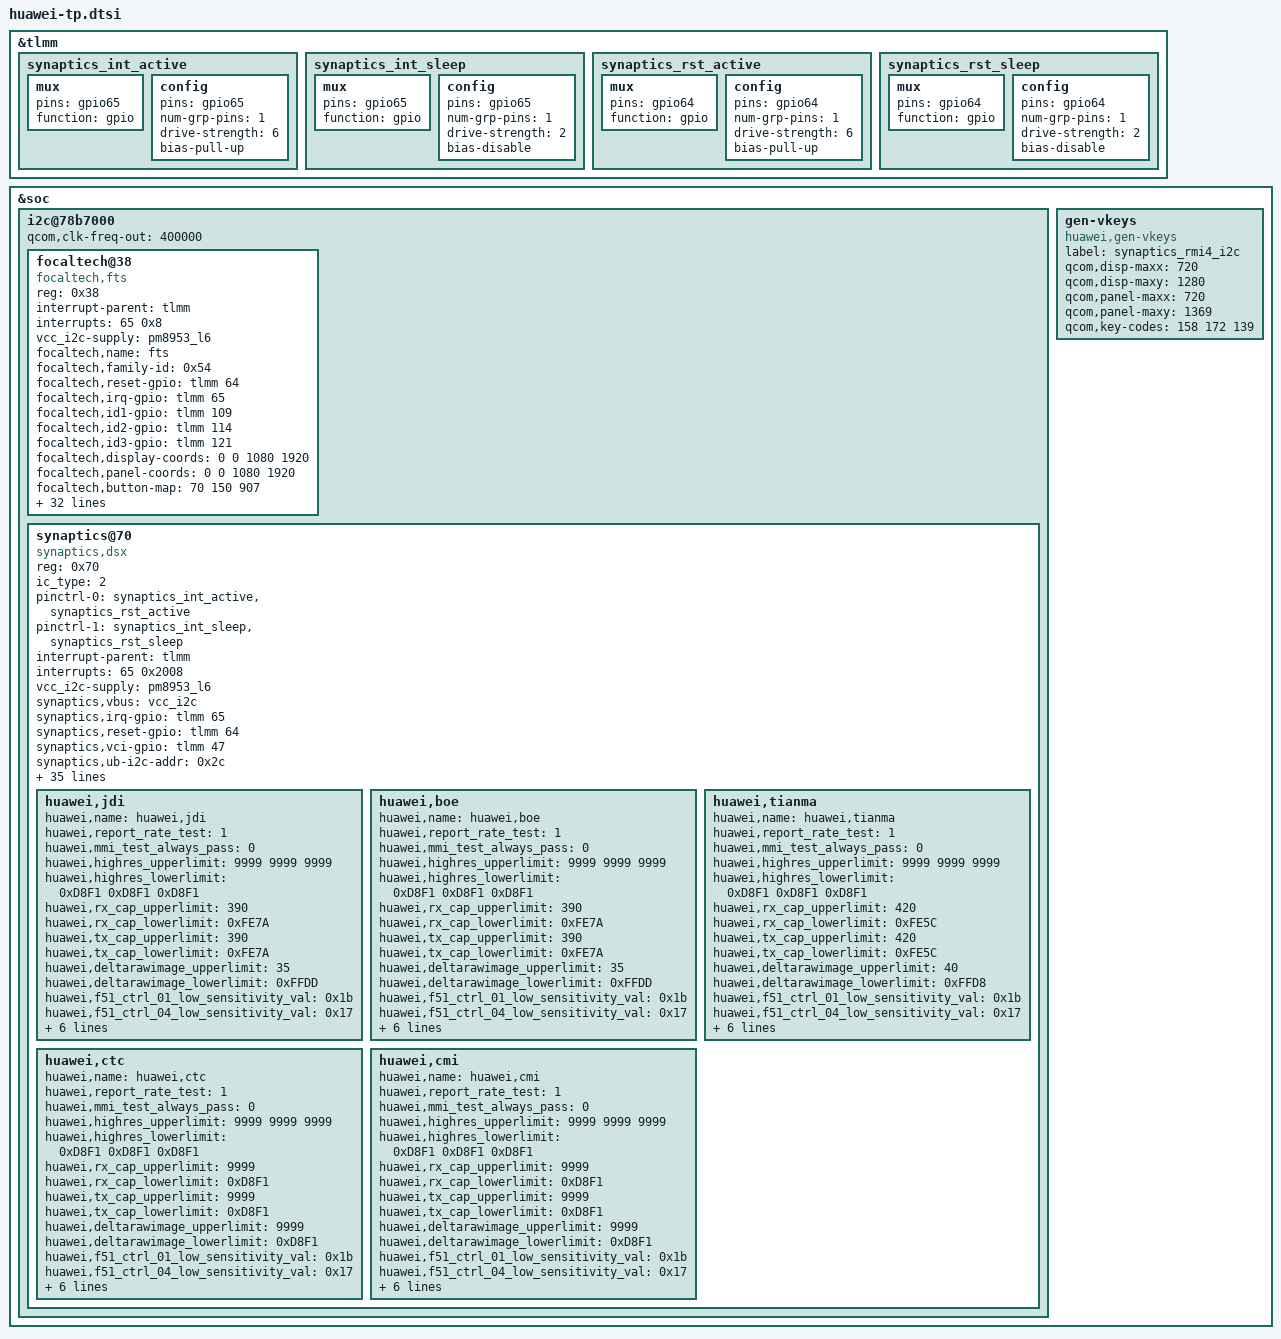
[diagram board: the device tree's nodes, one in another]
/* Modify JDI tp/lcd power on/off to reduce power consumption */
/* Modify JDI tp reset gpio pinctrl for power consumption */
/*Ath TP not working in glove mode*/
/* move l16 control to ATH device config file */
&tlmm {
	synaptics_int_active: synaptics_int_active{
			mux {
				pins = "gpio65";
				function =  "gpio";
			};
			config {
				pins = "gpio65";
				num-grp-pins = <1>;
				drive-strength = <6>;
				bias-pull-up;
		};
	};
	synaptics_int_sleep: synaptics_int_sleep {
			mux {
				pins = "gpio65";
				function =  "gpio";
			};
			config {
				pins = "gpio65";
				num-grp-pins = <1>;
				drive-strength = <2>;
				bias-disable;
		};
	};
	synaptics_rst_active: synaptics_rst_active {
			mux {
				pins = "gpio64";
				function =  "gpio";
			};
			config {
				pins = "gpio64";
				num-grp-pins = <1>;
				drive-strength = <6>;
				bias-pull-up;
			};
		};
	synaptics_rst_sleep: synaptics_rst_sleep {
			mux {
				pins = "gpio64";
				function =  "gpio";
			};
			config {
				pins = "gpio64";
				num-grp-pins = <1>;
				drive-strength = <2>;
				bias-disable;
		};
	};
};

&soc {
	i2c@78b7000 { /* BLSP1 QUP5 */
		status = "ok";
		#address-cells = <1>;
		#size-cells = <0>;
		qcom,clk-freq-out = <400000>;
		focaltech@38 {
			compatible = "focaltech,fts";
			reg = <0x38>;
			interrupt-parent = <&tlmm>;
			interrupts = <65 0x8>;
			vcc_i2c-supply = <&pm8953_l6>;
			focaltech,name = "fts";
			focaltech,family-id = <0x54>;
			focaltech,reset-gpio = <&tlmm 64 0x00>;
			focaltech,irq-gpio =<&tlmm 65 0x00>;
			focaltech,id1-gpio = <&tlmm 109 0x00>;
			focaltech,id2-gpio = <&tlmm 114 0x00>;
			focaltech,id3-gpio = <&tlmm 121 0x00>;
			focaltech,display-coords = <0 0 1080 1920>;
			focaltech,panel-coords = <0 0 1080 1920>;
			focaltech,button-map= <70 150 907>;
			focaltech,no-force-update;
			focaltech,i2c-pull-up;
			focaltech,group-id = <1>;
			focaltech,hard-reset-delay-ms = <20>;
			focaltech,soft-reset-delay-ms = <150>;
			focaltech,num-max-touches = <10>;
			focaltech,fw-name = "FT_Upgrade_App.i";
			focaltech,fw-delay-aa-ms = <50>;
			focaltech,fw-delay-55-ms = <30>;
			focaltech,fw-upgrade-id1 = <0x79>;
			focaltech,fw-upgrade-id2 = <0x03>;
			focaltech,fw-delay-readid-ms = <10>;
			focaltech,fw-delay-era-flsh-ms = <2000>;
			focaltech,channel_Xnum = <18>;
			focaltech,channel_Ynum = <30>;
			focaltech,cbunif_maxmin = <27>;
			focaltech,cbunif_chx_linearity = <70>;
			focaltech,cbunif_chy_linearity = <70>;
			focaltech,fullraw_upperlimit =
				<10000 10000 10000 10000 10000 10000 10000 10000 10000 10000 10000 10000 10000 10000 10000 10000 10000 10000 10000 10000 10000 10000 10000 10000 10000 10000 10000 10000 10000 10000
				10000 10000 10000 10000 10000 10000 10000 10000 10000 10000 10000 10000 10000 10000 10000 10000 10000 10000 10000 10000 10000 10000 10000 10000 10000 10000 10000 10000 10000 10000
				10000 10000 10000 10000 10000 10000 10000 10000 10000 10000 10000 10000 10000 10000 10000 10000 10000 10000 10000 10000 10000 10000 10000 10000 10000 10000 10000 10000 10000 10000
				10000 10000 10000 10000 10000 10000 10000 10000 10000 10000 10000 10000 10000 10000 10000 10000 10000 10000 10000 10000 10000 10000 10000 10000 10000 10000 10000 10000 10000 10000
				10000 10000 10000 10000 10000 10000 10000 10000 10000 10000 10000 10000 10000 10000 10000 10000 10000 10000 10000 10000 10000 10000 10000 10000 10000 10000 10000 10000 10000 10000
				10000 10000 10000 10000 10000 10000 10000 10000 10000 10000 10000 10000 10000 10000 10000 10000 10000 10000 10000 10000 10000 10000 10000 10000 10000 10000 10000 10000 10000 10000
				10000 10000 10000 10000 10000 10000 10000 10000 10000 10000 10000 10000 10000 10000 10000 10000 10000 10000 10000 10000 10000 10000 10000 10000 10000 10000 10000 10000 10000 10000
				10000 10000 10000 10000 10000 10000 10000 10000 10000 10000 10000 10000 10000 10000 10000 10000 10000 10000 10000 10000 10000 10000 10000 10000 10000 10000 10000 10000 10000 10000
				10000 10000 10000 10000 10000 10000 10000 10000 10000 10000 10000 10000 10000 10000 10000 10000 10000 10000 10000 10000 10000 10000 10000 10000 10000 10000 10000 10000 10000 10000
				10000 10000 10000 10000 10000 10000 10000 10000 10000 10000 10000 10000 10000 10000 10000 10000 10000 10000 10000 10000 10000 10000 10000 10000 10000 10000 10000 10000 10000 10000
				10000 10000 10000 10000 10000 10000 10000 10000 10000 10000 10000 10000 10000 10000 10000 10000 10000 10000 10000 10000 10000 10000 10000 10000 10000 10000 10000 10000 10000 10000
				10000 10000 10000 10000 10000 10000 10000 10000 10000 10000 10000 10000 10000 10000 10000 10000 10000 10000 10000 10000 10000 10000 10000 10000 10000 10000 10000 10000 10000 10000
				10000 10000 10000 10000 10000 10000 10000 10000 10000 10000 10000 10000 10000 10000 10000 10000 10000 10000 10000 10000 10000 10000 10000 10000 10000 10000 10000 10000 10000 10000
				10000 10000 10000 10000 10000 10000 10000 10000 10000 10000 10000 10000 10000 10000 10000 10000 10000 10000 10000 10000 10000 10000 10000 10000 10000 10000 10000 10000 10000 10000
				10000 10000 10000 10000 10000 10000 10000 10000 10000 10000 10000 10000 10000 10000 10000 10000 10000 10000 10000 10000 10000 10000 10000 10000 10000 10000 10000 10000 10000 10000
				10000 10000 10000 10000 10000 10000 10000 10000 10000 10000 10000 10000 10000 10000 10000 10000 10000 10000 10000 10000 10000 10000 10000 10000 10000 10000 10000 10000 10000 10000
				10000 10000 10000 10000 10000 10000 10000 10000 10000 10000 10000 10000 10000 10000 10000 10000 10000 10000 10000 10000 10000 10000 10000 10000 10000 10000 10000 10000 10000 10000
				10000 10000 10000 10000 10000 10000 10000 10000 10000 10000 10000 10000 10000 10000 10000 10000 10000 10000 10000 10000 10000 10000 10000 10000 10000 10000 10000 10000 10000 10000>;
			focaltech,fullraw_lowerlimit =
				<6500 6500 6500 6500 6500 6500 6500 6500 6500 6500 6500 6500 6500 6500 6500 6500 6500 6500 6500 6500 6500 6500 6500 6500 6500 6500 6500 6500 6500 6500
				6500 6500 6500 6500 6500 6500 6500 6500 6500 6500 6500 6500 6500 6500 6500 6500 6500 6500 6500 6500 6500 6500 6500 6500 6500 6500 6500 6500 6500 6500
				6500 6500 6500 6500 6500 6500 6500 6500 6500 6500 6500 6500 6500 6500 6500 6500 6500 6500 6500 6500 6500 6500 6500 6500 6500 6500 6500 6500 6500 6500
				6500 6500 6500 6500 6500 6500 6500 6500 6500 6500 6500 6500 6500 6500 6500 6500 6500 6500 6500 6500 6500 6500 6500 6500 6500 6500 6500 6500 6500 6500
				6500 6500 6500 6500 6500 6500 6500 6500 6500 6500 6500 6500 6500 6500 6500 6500 6500 6500 6500 6500 6500 6500 6500 6500 6500 6500 6500 6500 6500 6500
				6500 6500 6500 6500 6500 6500 6500 6500 6500 6500 6500 6500 6500 6500 6500 6500 6500 6500 6500 6500 6500 6500 6500 6500 6500 6500 6500 6500 6500 6500
				6500 6500 6500 6500 6500 6500 6500 6500 6500 6500 6500 6500 6500 6500 6500 6500 6500 6500 6500 6500 6500 6500 6500 6500 6500 6500 6500 6500 6500 6500
				6500 6500 6500 6500 6500 6500 6500 6500 6500 6500 6500 6500 6500 6500 6500 6500 6500 6500 6500 6500 6500 6500 6500 6500 6500 6500 6500 6500 6500 6500
				6500 6500 6500 6500 6500 6500 6500 6500 6500 6500 6500 6500 6500 6500 6500 6500 6500 6500 6500 6500 6500 6500 6500 6500 6500 6500 6500 6500 6500 6500
				6500 6500 6500 6500 6500 6500 6500 6500 6500 6500 6500 6500 6500 6500 6500 6500 6500 6500 6500 6500 6500 6500 6500 6500 6500 6500 6500 6500 6500 6500
				6500 6500 6500 6500 6500 6500 6500 6500 6500 6500 6500 6500 6500 6500 6500 6500 6500 6500 6500 6500 6500 6500 6500 6500 6500 6500 6500 6500 6500 6500
				6500 6500 6500 6500 6500 6500 6500 6500 6500 6500 6500 6500 6500 6500 6500 6500 6500 6500 6500 6500 6500 6500 6500 6500 6500 6500 6500 6500 6500 6500
				6500 6500 6500 6500 6500 6500 6500 6500 6500 6500 6500 6500 6500 6500 6500 6500 6500 6500 6500 6500 6500 6500 6500 6500 6500 6500 6500 6500 6500 6500
				6500 6500 6500 6500 6500 6500 6500 6500 6500 6500 6500 6500 6500 6500 6500 6500 6500 6500 6500 6500 6500 6500 6500 6500 6500 6500 6500 6500 6500 6500
				6500 6500 6500 6500 6500 6500 6500 6500 6500 6500 6500 6500 6500 6500 6500 6500 6500 6500 6500 6500 6500 6500 6500 6500 6500 6500 6500 6500 6500 6500
				6500 6500 6500 6500 6500 6500 6500 6500 6500 6500 6500 6500 6500 6500 6500 6500 6500 6500 6500 6500 6500 6500 6500 6500 6500 6500 6500 6500 6500 6500
				6500 6500 6500 6500 6500 6500 6500 6500 6500 6500 6500 6500 6500 6500 6500 6500 6500 6500 6500 6500 6500 6500 6500 6500 6500 6500 6500 6500 6500 6500
				6500 6500 6500 6500 6500 6500 6500 6500 6500 6500 6500 6500 6500 6500 6500 6500 6500 6500 6500 6500 6500 6500 6500 6500 6500 6500 6500 6500 6500 6500>;
			focaltech,fullcb_upperlimit =
				<22 22 22 22 22 22 22 22 22 22 22 22 22 22 22 22 22 22 22 22 22 22 22 22 22 22 22 22 22 22
				22 22 22 22 22 22 22 22 22 22 22 22 22 22 22 22 22 22 22 22 22 22 22 22 22 22 22 22 22 22
				22 22 22 22 22 22 22 22 22 22 22 22 22 22 22 22 22 22 22 22 22 22 22 22 22 22 22 22 22 22
				22 22 22 22 22 22 22 22 22 22 22 22 22 22 22 22 22 22 22 22 22 22 22 22 22 22 22 22 22 22
				22 22 22 22 22 22 22 22 22 22 22 22 22 22 22 22 22 22 22 22 22 22 22 22 22 22 22 22 22 22
				22 22 22 22 22 22 22 22 22 22 22 22 22 22 22 22 22 22 22 22 22 22 22 22 22 22 22 22 22 22
				22 22 22 22 22 22 22 22 22 22 22 22 22 22 22 22 22 22 22 22 22 22 22 22 22 22 22 22 22 22
				22 22 22 22 22 22 22 22 22 22 22 22 22 22 22 22 22 22 22 22 22 22 22 22 22 22 22 22 22 22
				22 22 22 22 22 22 22 22 22 22 22 22 22 22 22 22 22 22 22 22 22 22 22 22 22 22 22 22 22 22
				22 22 22 22 22 22 22 22 22 22 22 22 22 22 22 22 22 22 22 22 22 22 22 22 22 22 22 22 22 22
				22 22 22 22 22 22 22 22 22 22 22 22 22 22 22 22 22 22 22 22 22 22 22 22 22 22 22 22 22 22
				22 22 22 22 22 22 22 22 22 22 22 22 22 22 22 22 22 22 22 22 22 22 22 22 22 22 22 22 22 22
				22 22 22 22 22 22 22 22 22 22 22 22 22 22 22 22 22 22 22 22 22 22 22 22 22 22 22 22 22 22
				22 22 22 22 22 22 22 22 22 22 22 22 22 22 22 22 22 22 22 22 22 22 22 22 22 22 22 22 22 22
				22 22 22 22 22 22 22 22 22 22 22 22 22 22 22 22 22 22 22 22 22 22 22 22 22 22 22 22 22 22
				22 22 22 22 22 22 22 22 22 22 22 22 22 22 22 22 22 22 22 22 22 22 22 22 22 22 22 22 22 22
				22 22 22 22 22 22 22 22 22 22 22 22 22 22 22 22 22 22 22 22 22 22 22 22 22 22 22 22 22 22
				22 22 22 22 22 22 22 22 22 22 22 22 22 22 22 22 22 22 22 22 22 22 22 22 22 22 22 22 22 22>;
			focaltech,fullcb_lowerlimit =
				<6 6 6 6 6 6 6 6 6 6 6 6 6 6 6 6 6 6 6 6 6 6 6 6 6 6 6 6 6 6
				6 6 6 6 6 6 6 6 6 6 6 6 6 6 6 6 6 6 6 6 6 6 6 6 6 6 6 6 6 6
				6 6 6 6 6 6 6 6 6 6 6 6 6 6 6 6 6 6 6 6 6 6 6 6 6 6 6 6 6 6
				6 6 6 6 6 6 6 6 6 6 6 6 6 6 6 6 6 6 6 6 6 6 6 6 6 6 6 6 6 6
				6 6 6 6 6 6 6 6 6 6 6 6 6 6 6 6 6 6 6 6 6 6 6 6 6 6 6 6 6 6
				6 6 6 6 6 6 6 6 6 6 6 6 6 6 6 6 6 6 6 6 6 6 6 6 6 6 6 6 6 6
				6 6 6 6 6 6 6 6 6 6 6 6 6 6 6 6 6 6 6 6 6 6 6 6 6 6 6 6 6 6
				6 6 6 6 6 6 6 6 6 6 6 6 6 6 6 6 6 6 6 6 6 6 6 6 6 6 6 6 6 6
				6 6 6 6 6 6 6 6 6 6 6 6 6 6 6 6 6 6 6 6 6 6 6 6 6 6 6 6 6 6
				6 6 6 6 6 6 6 6 6 6 6 6 6 6 6 6 6 6 6 6 6 6 6 6 6 6 6 6 6 6
				6 6 6 6 6 6 6 6 6 6 6 6 6 6 6 6 6 6 6 6 6 6 6 6 6 6 6 6 6 6
				6 6 6 6 6 6 6 6 6 6 6 6 6 6 6 6 6 6 6 6 6 6 6 6 6 6 6 6 6 6
				6 6 6 6 6 6 6 6 6 6 6 6 6 6 6 6 6 6 6 6 6 6 6 6 6 6 6 6 6 6
				6 6 6 6 6 6 6 6 6 6 6 6 6 6 6 6 6 6 6 6 6 6 6 6 6 6 6 6 6 6
				6 6 6 6 6 6 6 6 6 6 6 6 6 6 6 6 6 6 6 6 6 6 6 6 6 6 6 6 6 6
				6 6 6 6 6 6 6 6 6 6 6 6 6 6 6 6 6 6 6 6 6 6 6 6 6 6 6 6 6 6
				6 6 6 6 6 6 6 6 6 6 6 6 6 6 6 6 6 6 6 6 6 6 6 6 6 6 6 6 6 6
				6 6 6 6 6 6 6 6 6 6 6 6 6 6 6 6 6 6 6 6 6 6 6 6 6 6 6 6 6 6>;
			focaltech,fts_noise_limit =
				<120 120 120 120 120 120 120 120 120 120 120 120 120 120 120 120 120 120 120 120 120 120 120 120 120 120 120 120 120 120
				120 120 120 120 120 120 120 120 120 120 120 120 120 120 120 120 120 120 120 120 120 120 120 120 120 120 120 120 120 120
				120 120 120 120 120 120 120 120 120 120 120 120 120 120 120 120 120 120 120 120 120 120 120 120 120 120 120 120 120 120
				120 120 120 120 120 120 120 120 120 120 120 120 120 120 120 120 120 120 120 120 120 120 120 120 120 120 120 120 120 120
				120 120 120 120 120 120 120 120 120 120 120 120 120 120 120 120 120 120 120 120 120 120 120 120 120 120 120 120 120 120
				120 120 120 120 120 120 120 120 120 120 120 120 120 120 120 120 120 120 120 120 120 120 120 120 120 120 120 120 120 120
				120 120 120 120 120 120 120 120 120 120 120 120 120 120 120 120 120 120 120 120 120 120 120 120 120 120 120 120 120 120
				120 120 120 120 120 120 120 120 120 120 120 120 120 120 120 120 120 120 120 120 120 120 120 120 120 120 120 120 120 120
				120 120 120 120 120 120 120 120 120 120 120 120 120 120 120 120 120 120 120 120 120 120 120 120 120 120 120 120 120 120
				120 120 120 120 120 120 120 120 120 120 120 120 120 120 120 120 120 120 120 120 120 120 120 120 120 120 120 120 120 120
				120 120 120 120 120 120 120 120 120 120 120 120 120 120 120 120 120 120 120 120 120 120 120 120 120 120 120 120 120 120
				120 120 120 120 120 120 120 120 120 120 120 120 120 120 120 120 120 120 120 120 120 120 120 120 120 120 120 120 120 120
				120 120 120 120 120 120 120 120 120 120 120 120 120 120 120 120 120 120 120 120 120 120 120 120 120 120 120 120 120 120
				120 120 120 120 120 120 120 120 120 120 120 120 120 120 120 120 120 120 120 120 120 120 120 120 120 120 120 120 120 120
				120 120 120 120 120 120 120 120 120 120 120 120 120 120 120 120 120 120 120 120 120 120 120 120 120 120 120 120 120 120
				120 120 120 120 120 120 120 120 120 120 120 120 120 120 120 120 120 120 120 120 120 120 120 120 120 120 120 120 120 120
				120 120 120 120 120 120 120 120 120 120 120 120 120 120 120 120 120 120 120 120 120 120 120 120 120 120 120 120 120 120
				120 120 120 120 120 120 120 120 120 120 120 120 120 120 120 120 120 120 120 120 120 120 120 120 120 120 120 120 120 120>;
			focaltech,fts_tx2tx_limit =
				<3500 3500 3500 3500 3500 3500 3500 3500 3500 3500 3500 3500 3500 3500 3500 3500 3500 3500 3500 3500 3500 3500 3500 3500 3500 3500 3500 3500 3500 3500
				3500 3500 3500 3500 3500 3500 3500 3500 3500 3500 3500 3500 3500 3500 3500 3500 3500 3500 3500 3500 3500 3500 3500 3500 3500 3500 3500 3500 3500 3500
				3500 3500 3500 3500 3500 3500 3500 3500 3500 3500 3500 3500 3500 3500 3500 3500 3500 3500 3500 3500 3500 3500 3500 3500 3500 3500 3500 3500 3500 3500
				3500 3500 3500 3500 3500 3500 3500 3500 3500 3500 3500 3500 3500 3500 3500 3500 3500 3500 3500 3500 3500 3500 3500 3500 3500 3500 3500 3500 3500 3500
				3500 3500 3500 3500 3500 3500 3500 3500 3500 3500 3500 3500 3500 3500 3500 3500 3500 3500 3500 3500 3500 3500 3500 3500 3500 3500 3500 3500 3500 3500
				3500 3500 3500 3500 3500 3500 3500 3500 3500 3500 3500 3500 3500 3500 3500 3500 3500 3500 3500 3500 3500 3500 3500 3500 3500 3500 3500 3500 3500 3500
				3500 3500 3500 3500 3500 3500 3500 3500 3500 3500 3500 3500 3500 3500 3500 3500 3500 3500 3500 3500 3500 3500 3500 3500 3500 3500 3500 3500 3500 3500
				3500 3500 3500 3500 3500 3500 3500 3500 3500 3500 3500 3500 3500 3500 3500 3500 3500 3500 3500 3500 3500 3500 3500 3500 3500 3500 3500 3500 3500 3500
				3500 3500 3500 3500 3500 3500 3500 3500 3500 3500 3500 3500 3500 3500 3500 3500 3500 3500 3500 3500 3500 3500 3500 3500 3500 3500 3500 3500 3500 3500
				3500 3500 3500 3500 3500 3500 3500 3500 3500 3500 3500 3500 3500 3500 3500 3500 3500 3500 3500 3500 3500 3500 3500 3500 3500 3500 3500 3500 3500 3500
				3500 3500 3500 3500 3500 3500 3500 3500 3500 3500 3500 3500 3500 3500 3500 3500 3500 3500 3500 3500 3500 3500 3500 3500 3500 3500 3500 3500 3500 3500
				3500 3500 3500 3500 3500 3500 3500 3500 3500 3500 3500 3500 3500 3500 3500 3500 3500 3500 3500 3500 3500 3500 3500 3500 3500 3500 3500 3500 3500 3500
				3500 3500 3500 3500 3500 3500 3500 3500 3500 3500 3500 3500 3500 3500 3500 3500 3500 3500 3500 3500 3500 3500 3500 3500 3500 3500 3500 3500 3500 3500
				3500 3500 3500 3500 3500 3500 3500 3500 3500 3500 3500 3500 3500 3500 3500 3500 3500 3500 3500 3500 3500 3500 3500 3500 3500 3500 3500 3500 3500 3500
				3500 3500 3500 3500 3500 3500 3500 3500 3500 3500 3500 3500 3500 3500 3500 3500 3500 3500 3500 3500 3500 3500 3500 3500 3500 3500 3500 3500 3500 3500
				3500 3500 3500 3500 3500 3500 3500 3500 3500 3500 3500 3500 3500 3500 3500 3500 3500 3500 3500 3500 3500 3500 3500 3500 3500 3500 3500 3500 3500 3500
				3500 3500 3500 3500 3500 3500 3500 3500 3500 3500 3500 3500 3500 3500 3500 3500 3500 3500 3500 3500 3500 3500 3500 3500 3500 3500 3500 3500 3500 3500>;
			focaltech,fts_rx2rx_limit =
				<3500 3500 3500 3500 3500 3500 3500 3500 3500 3500 3500 3500 3500 3500 3500 3500 3500 3500 3500 3500 3500 3500 3500 3500 3500 3500 3500 3500 3500
				3500 3500 3500 3500 3500 3500 3500 3500 3500 3500 3500 3500 3500 3500 3500 3500 3500 3500 3500 3500 3500 3500 3500 3500 3500 3500 3500 3500 3500
				3500 3500 3500 3500 3500 3500 3500 3500 3500 3500 3500 3500 3500 3500 3500 3500 3500 3500 3500 3500 3500 3500 3500 3500 3500 3500 3500 3500 3500
				3500 3500 3500 3500 3500 3500 3500 3500 3500 3500 3500 3500 3500 3500 3500 3500 3500 3500 3500 3500 3500 3500 3500 3500 3500 3500 3500 3500 3500
				3500 3500 3500 3500 3500 3500 3500 3500 3500 3500 3500 3500 3500 3500 3500 3500 3500 3500 3500 3500 3500 3500 3500 3500 3500 3500 3500 3500 3500
				3500 3500 3500 3500 3500 3500 3500 3500 3500 3500 3500 3500 3500 3500 3500 3500 3500 3500 3500 3500 3500 3500 3500 3500 3500 3500 3500 3500 3500
				3500 3500 3500 3500 3500 3500 3500 3500 3500 3500 3500 3500 3500 3500 3500 3500 3500 3500 3500 3500 3500 3500 3500 3500 3500 3500 3500 3500 3500
				3500 3500 3500 3500 3500 3500 3500 3500 3500 3500 3500 3500 3500 3500 3500 3500 3500 3500 3500 3500 3500 3500 3500 3500 3500 3500 3500 3500 3500
				3500 3500 3500 3500 3500 3500 3500 3500 3500 3500 3500 3500 3500 3500 3500 3500 3500 3500 3500 3500 3500 3500 3500 3500 3500 3500 3500 3500 3500
				3500 3500 3500 3500 3500 3500 3500 3500 3500 3500 3500 3500 3500 3500 3500 3500 3500 3500 3500 3500 3500 3500 3500 3500 3500 3500 3500 3500 3500
				3500 3500 3500 3500 3500 3500 3500 3500 3500 3500 3500 3500 3500 3500 3500 3500 3500 3500 3500 3500 3500 3500 3500 3500 3500 3500 3500 3500 3500
				3500 3500 3500 3500 3500 3500 3500 3500 3500 3500 3500 3500 3500 3500 3500 3500 3500 3500 3500 3500 3500 3500 3500 3500 3500 3500 3500 3500 3500
				3500 3500 3500 3500 3500 3500 3500 3500 3500 3500 3500 3500 3500 3500 3500 3500 3500 3500 3500 3500 3500 3500 3500 3500 3500 3500 3500 3500 3500
				3500 3500 3500 3500 3500 3500 3500 3500 3500 3500 3500 3500 3500 3500 3500 3500 3500 3500 3500 3500 3500 3500 3500 3500 3500 3500 3500 3500 3500
				3500 3500 3500 3500 3500 3500 3500 3500 3500 3500 3500 3500 3500 3500 3500 3500 3500 3500 3500 3500 3500 3500 3500 3500 3500 3500 3500 3500 3500
				3500 3500 3500 3500 3500 3500 3500 3500 3500 3500 3500 3500 3500 3500 3500 3500 3500 3500 3500 3500 3500 3500 3500 3500 3500 3500 3500 3500 3500
				3500 3500 3500 3500 3500 3500 3500 3500 3500 3500 3500 3500 3500 3500 3500 3500 3500 3500 3500 3500 3500 3500 3500 3500 3500 3500 3500 3500 3500
				3500 3500 3500 3500 3500 3500 3500 3500 3500 3500 3500 3500 3500 3500 3500 3500 3500 3500 3500 3500 3500 3500 3500 3500 3500 3500 3500 3500 3500>;
		};
		synaptics@70 {
			compatible = "synaptics,dsx";
			reg = <0x70>;

			/* SYNAPTICS_S3207 = 0 */
			/* SYNAPTICS_S3350 = 1 */
			/* SYNAPTICS_S3320 = 2 */
			/* SYNAPTICS_S3718 = 3 */
			ic_type = <2>;

			pinctrl-names = "active","sleep";
			pinctrl-0 = <&synaptics_int_active &synaptics_rst_active>;
			pinctrl-1 = <&synaptics_int_sleep &synaptics_rst_sleep>;

			interrupt-parent = <&tlmm>;
			interrupts = <65 0x2008>;
			vcc_i2c-supply = <&pm8953_l6>;
			/* Some of qcom's param will not be replaced by huawei in dtb, */
			/* just ignore them:such as "pinctrl-names","pinctrl-0","pinctrl-1", */
			/* "synaptics,display-coords","synaptics,panel-coords","synaptics,i2c-pull-up", */
			/* "synaptics,power-down","synaptics,disable-gpios"*/
			//synaptics,vdd = "vdd";
			synaptics,vbus = "vcc_i2c";
			synaptics,irq-gpio = <&tlmm 65 0x2008>;
			synaptics,reset-gpio = <&tlmm 64 0x0>;
			synaptics,vci-gpio = <&tlmm 47 0x0>;
			synaptics,ub-i2c-addr=<0x2c>;
			synaptics,i2c-addr=<0x70>;

			/* synaptics,sleep/wake strategy */

			/* SLEEP_STRATEGY_DEEP_SLEEP    : 0*/
			/* SLEEP_STRATEGY_POWER_DOWN    : 1*/
			/* SLEEP_STRATEGY_KEEP_WAKE     : 2*/
			/* SLEEP_STRATEGY_ALWAYS_RESET  : 3*/
			synaptics,sleep-strategy = <3>;

			synaptics,lcd-x = <1080>;
			synaptics,lcd-y = <1920>;
			synaptics,lcd-all = <1920>;
			synaptics,virtual_keys = /* KeyCode CenterX CenterY Width Height */
				/* KEY_BACK */
				<158 142 1342 150 100
				/* KEY_HOME(172) */
				172 360 1342 150 100
				/* KEY_MENU */
				139 578 1342 150 100>;

			/* SYNAPTICS_WAKE_UP_GESTURE_FLAG:'1'->enabled,'0'->disabled */
			/*IC flash is not enough for holster,so fw del one gesture*/
			synaptics,gesture_enabled = <0>;
			/* Gestures that supported:                           */
			/* bit0  Double tap                                        */
			/* bit1  Single finger slide from left to right     */
			/* bit2  Single finger slide from right to left     */
			/* bit3  Single finger slide from top to bottom  */
			/* bit4  Single finger slide from bottom to top  */
			/* bit5  Double finger slide from top to bottom--disable for holster*/
			/* bit6  Single finger slide circle                     */
			/* bit7  Single finger write letter c                  */
			/* bit8  Single finger write letter e                  */
			/* bit9  Single finger write letter m                 */
			/* bit10 Single finger write letter w                 */
			/* bit11 Palm off screen                                */
			synaptics,easy_wakeup_supported_gestures = <0xF81>;

			/*Defination of report key value  for different gestures*/
			synaptics,easy_wakeup_gesture_keys =
			<	59 /*0.Double tap:                                  KEY_F1*/
				60 /*1.Single finger slide from left to right:      KEY_F2*/
				61 /*2.Single finger slide from right to left:      KEY_F3*/
				62 /*3.Single finger slide from top to bottom:      KEY_F4*/
				63 /*4.Single finger slide from bottom to top:      KEY_F5*/
				64 /*5.Single finger slide circle clockwise:        KEY_F6*/
				65 /*6.Single finger slide circle counter-clockwise:KEY_F7*/
				66 /*7.Single finger write letter c:                KEY_F8*/
				67 /*8.Single finger write letter e:                KEY_F9*/
				68 /*9.Single finger write letter m:                KEY_F10*/
				87 /*10.Single finger write letter w:               KEY_F11*/
				88 /*11.Palm off screen:                            KEY_F12*/
			>;

			/* Double-tap-zone defined by huawei */
			/* Shielded area is:1cm left,1cm right,3cm up,2cm down */
			huawei,dtz_x0 = <1>;
			huawei,dtz_y0 = <1>;
			huawei,dtz_x1 = <1080>;
			huawei,dtz_y1 = <1920>;

			/* GLOVE FLAG default state:'1'->enabled,'0'->disabled*/
			synaptics,glove_enabled = <0>;
			/*After reduce power-consumption by exit reduce mode,*/
			/*we have to reduce f-r rate to make sure gesture work fine*/
			synaptics,fast_relax_gesture = <0>;
			/*Holster support flag*/
			synaptics,holster_supported = <1>;
			synaptics,roi_supported = <1>;
			synaptics,glove_edge_switch_supported = <0>;
			synaptics,grip_algorithm_supported = <0>;
			synaptics,grip_algorithm_enabled = <0>;
			huawei,grip_left_lsb = <0x32>;
			huawei,grip_left_msb = <0x0>;
			huawei,grip_right_lsb = <0x1A>;
			huawei,grip_right_msb = <0x04>;

			/*dwt represent doze wakeup threshold in gesture mode*/
			synaptics,ofilm_dwt = <30>;
			synaptics,truly_dwt = <30>;
			synaptics,junda_dwt = <30>;

			synaptics,reset-on-status = <0>;
			synaptics,power-delay-ms = <160>;
			synaptics,reset-delay-ms = <200>;
			synaptics,reset-active-ms = <10>;
			synaptics,product_name = "milan";

			/*capacitance self-adapt*/
			huawei,jdi {
				huawei,name = "huawei,jdi";
				huawei,report_rate_test = <1>; /* 0:disable test, 1:enable test */
				huawei,mmi_test_always_pass = <0>;

				huawei,highres_upperlimit = <9999 9999 9999>;
				huawei,highres_lowerlimit = <0xD8F1 0xD8F1 0xD8F1>;/* 0xD8F1 == -9999 */

				huawei,rx_cap_upperlimit = <390>;
				huawei,rx_cap_lowerlimit = <0xFE7A>;

				huawei,tx_cap_upperlimit = <390>;
				huawei,tx_cap_lowerlimit = <0xFE7A>;

				huawei,deltarawimage_upperlimit = <35>;
				huawei,deltarawimage_lowerlimit = <0xFFDD>;				

				huawei,f51_ctrl_01_low_sensitivity_val = <0x1b>;
				huawei,f51_ctrl_04_low_sensitivity_val = <0x17>;
				huawei,f01_ctrl_05_low_sensitivity_val = <0x05>;
				huawei,f01_ctrl_09_low_sensitivity_val = <0x04>;

				huawei,fullraw_upperlimit =
					<2437 2481 2476 2338 2306 2310 2304 2302 2298 2308 2303 2293 2291 2516 2485 2455 2397 
					2363 2407 2402 2264 2230 2234 2229 2226 2223 2233 2228 2217 2217 2441 2410 2382 2329 
					2369 2414 2407 2269 2236 2238 2234 2232 2228 2237 2232 2223 2221 2446 2415 2389 2336 
					2377 2421 2414 2275 2241 2245 2239 2237 2233 2243 2238 2228 2226 2451 2421 2395 2343 
					2384 2428 2420 2281 2247 2250 2245 2242 2238 2247 2243 2233 2233 2457 2427 2402 2349 
					2389 2433 2427 2288 2252 2255 2250 2246 2242 2252 2247 2238 2238 2462 2432 2406 2354 
					2394 2438 2432 2294 2258 2259 2252 2250 2246 2255 2251 2242 2242 2467 2437 2411 2358 
					2397 2441 2434 2297 2262 2262 2255 2252 2247 2258 2252 2243 2245 2470 2440 2414 2362 
					2398 2444 2436 2299 2263 2263 2256 2254 2250 2259 2254 2246 2246 2471 2441 2415 2363 
					2399 2444 2437 2299 2263 2264 2258 2254 2250 2259 2255 2246 2247 2471 2441 2416 2364 
					2398 2444 2436 2299 2263 2263 2256 2252 2249 2258 2254 2245 2246 2470 2441 2415 2364 
					2397 2441 2434 2297 2260 2260 2254 2251 2246 2255 2251 2243 2245 2468 2438 2412 2363 
					2394 2438 2431 2294 2258 2258 2251 2249 2243 2252 2249 2241 2242 2466 2436 2410 2360 
					2392 2434 2427 2291 2254 2254 2247 2245 2239 2250 2245 2237 2238 2462 2432 2406 2356 
					2388 2429 2423 2286 2249 2250 2243 2239 2236 2245 2241 2232 2234 2457 2428 2402 2354 
					2382 2424 2416 2281 2243 2243 2237 2234 2229 2239 2234 2226 2229 2451 2421 2397 2349 
					2377 2418 2410 2276 2237 2238 2232 2228 2224 2233 2229 2220 2223 2446 2416 2390 2343 
					2371 2411 2403 2269 2232 2232 2225 2221 2217 2226 2223 2215 2217 2440 2410 2385 2338 
					2364 2405 2397 2262 2224 2224 2219 2215 2211 2220 2216 2208 2211 2432 2403 2379 2332 
					2356 2395 2389 2255 2216 2216 2210 2207 2203 2212 2208 2200 2203 2424 2395 2371 2324 
					2349 2388 2381 2247 2210 2210 2203 2200 2197 2206 2202 2194 2197 2418 2388 2363 2317 
					2342 2380 2373 2241 2202 2202 2195 2193 2189 2198 2194 2186 2190 2411 2381 2355 2311 
					2334 2372 2366 2233 2194 2194 2187 2185 2181 2190 2186 2178 2182 2402 2372 2347 2303 
					2327 2363 2356 2224 2186 2186 2180 2177 2173 2182 2178 2171 2173 2393 2364 2338 2295 
					2319 2355 2347 2215 2177 2177 2172 2169 2165 2174 2171 2161 2165 2384 2355 2330 2288 
					2310 2346 2338 2206 2167 2169 2163 2161 2158 2167 2161 2152 2155 2375 2345 2321 2278 
					2302 2337 2329 2197 2159 2160 2155 2154 2150 2159 2154 2145 2147 2366 2337 2311 2271 
					2294 2328 2321 2191 2152 2152 2147 2145 2142 2150 2146 2137 2141 2359 2328 2303 2262 
					2290 2324 2317 2189 2150 2150 2143 2142 2139 2147 2142 2134 2138 2355 2324 2298 2258 
					2403 2442 2434 2316 2272 2269 2259 2263 2282 2275 2262 2258 2268 2476 2445 2419 2382>;

				huawei,fullraw_lowerlimit =
					<1312 1336 1333 1259 1241 1243 1241 1239 1237 1243 1240 1234 1234 1355 1338 1322 1290 
					1272 1296 1293 1219 1201 1203 1200 1199 1197 1202 1199 1194 1194 1314 1297 1283 1254 
					1276 1299 1296 1222 1204 1205 1203 1201 1199 1204 1201 1197 1196 1317 1300 1286 1257 
					1280 1304 1299 1225 1206 1208 1206 1204 1202 1208 1205 1199 1199 1320 1304 1290 1262 
					1283 1307 1303 1228 1210 1211 1208 1207 1205 1210 1208 1202 1202 1323 1306 1293 1264 
					1286 1310 1306 1232 1213 1214 1211 1209 1207 1213 1210 1205 1205 1325 1309 1295 1267 
					1289 1313 1309 1235 1215 1216 1213 1211 1209 1214 1212 1207 1207 1328 1312 1298 1269 
					1290 1314 1311 1236 1218 1218 1214 1213 1210 1215 1213 1208 1208 1330 1313 1299 1271 
					1291 1316 1311 1238 1218 1218 1215 1213 1211 1216 1213 1209 1209 1330 1314 1300 1272 
					1292 1316 1312 1238 1218 1219 1215 1213 1211 1216 1214 1209 1210 1330 1314 1301 1273 
					1291 1316 1311 1238 1218 1218 1215 1213 1211 1215 1213 1208 1209 1330 1314 1300 1273 
					1290 1314 1311 1236 1217 1217 1213 1212 1209 1214 1212 1208 1208 1329 1313 1299 1272 
					1289 1313 1309 1235 1215 1215 1212 1211 1208 1213 1211 1206 1207 1327 1311 1297 1271 
					1288 1311 1306 1234 1213 1213 1210 1208 1206 1211 1208 1204 1205 1325 1309 1295 1269 
					1285 1308 1304 1231 1211 1211 1208 1206 1204 1208 1206 1201 1203 1323 1307 1293 1267 
					1283 1305 1301 1228 1208 1208 1204 1203 1200 1206 1203 1199 1200 1320 1304 1290 1264 
					1280 1302 1297 1225 1204 1205 1201 1199 1197 1202 1200 1195 1197 1317 1301 1287 1262 
					1276 1298 1294 1222 1201 1201 1198 1196 1194 1199 1197 1192 1194 1313 1297 1284 1259 
					1273 1295 1290 1218 1197 1197 1194 1192 1190 1195 1193 1189 1190 1309 1294 1281 1255 
					1269 1290 1286 1214 1193 1193 1190 1188 1186 1191 1189 1185 1186 1305 1290 1276 1251 
					1264 1285 1282 1210 1190 1190 1186 1185 1183 1187 1185 1181 1183 1302 1285 1272 1248 
					1261 1281 1278 1206 1185 1185 1182 1180 1178 1183 1181 1177 1179 1298 1282 1268 1244 
					1257 1277 1274 1202 1181 1181 1178 1176 1174 1179 1177 1173 1175 1293 1277 1264 1240 
					1253 1272 1269 1197 1177 1177 1173 1172 1170 1175 1173 1169 1170 1288 1273 1259 1236 
					1248 1268 1264 1192 1172 1172 1169 1168 1166 1171 1169 1164 1166 1283 1268 1255 1232 
					1243 1263 1259 1187 1166 1168 1164 1164 1162 1166 1164 1159 1160 1278 1262 1250 1227 
					1239 1258 1254 1183 1162 1163 1160 1159 1157 1162 1159 1155 1156 1274 1258 1244 1222 
					1235 1253 1250 1180 1159 1159 1156 1155 1153 1157 1155 1150 1152 1270 1253 1240 1218 
					1233 1251 1248 1178 1157 1157 1154 1153 1152 1156 1153 1149 1151 1268 1251 1237 1215 
					1294 1315 1311 1247 1223 1222 1216 1218 1229 1225 1218 1215 1221 1333 1316 1302 1283>;
			};

			huawei,boe {
				huawei,name = "huawei,boe";
				huawei,report_rate_test = <1>; /* 0:disable test, 1:enable test */
				huawei,mmi_test_always_pass = <0>;

				huawei,highres_upperlimit = <9999 9999 9999>;
				huawei,highres_lowerlimit = <0xD8F1 0xD8F1 0xD8F1>;/* 0xD8F1 == -9999 */

				huawei,rx_cap_upperlimit = <390>;
				huawei,rx_cap_lowerlimit = <0xFE7A>;

				huawei,tx_cap_upperlimit = <390>;
				huawei,tx_cap_lowerlimit = <0xFE7A>;

				huawei,deltarawimage_upperlimit = <35>;
				huawei,deltarawimage_lowerlimit = <0xFFDD>;

				huawei,f51_ctrl_01_low_sensitivity_val = <0x1b>;
				huawei,f51_ctrl_04_low_sensitivity_val = <0x17>;
				huawei,f01_ctrl_05_low_sensitivity_val = <0x05>;
				huawei,f01_ctrl_09_low_sensitivity_val = <0x04>;

				huawei,fullraw_upperlimit =
					<3378 3430 3421 3378 3373 3333 3330 3320 3325 3334 3333 3359 3382 3395 3420 3400 
					3316 3381 3374 3328 3322 3282 3279 3270 3276 3285 3283 3309 3330 3346 3370 3333 
					3251 3315 3308 3263 3257 3218 3216 3207 3212 3221 3220 3244 3265 3279 3302 3266 
					3256 3320 3315 3269 3265 3225 3222 3214 3218 3227 3226 3251 3272 3286 3308 3272 
					3260 3325 3320 3274 3270 3230 3227 3220 3225 3234 3231 3256 3277 3291 3313 3276 
					3263 3328 3324 3278 3274 3234 3233 3224 3229 3238 3235 3260 3281 3295 3317 3279 
					3265 3330 3326 3281 3277 3237 3235 3226 3231 3240 3238 3263 3283 3298 3318 3281 
					3265 3331 3328 3282 3278 3239 3237 3229 3234 3242 3240 3264 3285 3299 3320 3282 
					3265 3331 3328 3282 3278 3239 3238 3230 3234 3243 3240 3265 3285 3298 3320 3281 
					3261 3329 3324 3279 3276 3237 3235 3227 3233 3240 3238 3263 3282 3295 3316 3277 
					3263 3330 3326 3282 3278 3239 3238 3230 3235 3243 3240 3264 3283 3296 3317 3278 
					3261 3329 3325 3281 3277 3238 3237 3229 3234 3242 3239 3263 3282 3295 3315 3276 
					3259 3326 3322 3278 3276 3237 3235 3227 3233 3240 3238 3261 3281 3292 3312 3273 
					3256 3324 3320 3277 3273 3235 3233 3225 3230 3238 3235 3259 3278 3290 3309 3269 
					3251 3318 3316 3272 3269 3231 3229 3221 3226 3234 3231 3255 3274 3286 3305 3265 
					3246 3313 3311 3268 3264 3226 3225 3217 3222 3230 3226 3250 3269 3281 3299 3259 
					3239 3307 3304 3261 3259 3221 3220 3212 3216 3225 3221 3244 3263 3274 3292 3252 
					3231 3300 3298 3255 3252 3214 3213 3205 3211 3218 3214 3238 3256 3268 3286 3244 
					3224 3292 3290 3247 3246 3208 3207 3199 3203 3212 3208 3231 3248 3260 3277 3237 
					3214 3282 3281 3238 3237 3199 3198 3190 3195 3203 3199 3222 3239 3251 3268 3227 
					3208 3276 3274 3233 3231 3194 3192 3185 3190 3198 3194 3217 3234 3246 3261 3221 
					3199 3266 3266 3224 3222 3186 3185 3178 3182 3190 3186 3208 3226 3237 3252 3212 
					3190 3259 3259 3216 3216 3178 3177 3170 3175 3183 3179 3201 3218 3229 3244 3203 
					3182 3251 3251 3209 3208 3172 3170 3164 3169 3175 3172 3194 3211 3221 3235 3194 
					3173 3242 3243 3201 3201 3165 3164 3157 3161 3169 3165 3187 3203 3212 3227 3186 
					3164 3234 3234 3194 3194 3157 3157 3151 3155 3162 3159 3179 3195 3204 3218 3177 
					3155 3225 3226 3187 3187 3151 3151 3146 3149 3156 3152 3173 3187 3196 3209 3168 
					3225 3298 3300 3260 3260 3225 3225 3218 3222 3230 3225 3246 3261 3269 3282 3238
					3291 3356 3356 3315 3315 3278 3277 3264 3269 3281 3276 3296 3312 3322 3334 3294>;

				huawei,fullraw_lowerlimit =
					<1819 1847 1842 1819 1816 1794 1793 1787 1790 1795 1794 1808 1821 1828 1841 1831 
					1785 1820 1817 1792 1789 1767 1766 1761 1764 1768 1768 1782 1793 1801 1815 1794 
					1750 1785 1781 1757 1754 1733 1731 1726 1729 1734 1733 1747 1758 1766 1778 1759 
					1753 1787 1785 1760 1758 1736 1735 1731 1733 1738 1737 1750 1761 1769 1781 1761 
					1755 1790 1787 1763 1761 1739 1738 1733 1736 1741 1740 1753 1764 1772 1784 1764 
					1757 1792 1789 1765 1763 1741 1740 1736 1738 1743 1742 1755 1766 1774 1786 1766 
					1758 1793 1791 1766 1764 1743 1742 1737 1740 1745 1743 1757 1768 1775 1787 1766 
					1758 1794 1792 1767 1765 1744 1743 1738 1741 1745 1745 1757 1768 1776 1787 1767 
					1758 1794 1792 1767 1765 1744 1743 1739 1741 1746 1745 1758 1768 1775 1787 1766 
					1756 1792 1789 1766 1764 1743 1742 1738 1740 1745 1743 1757 1767 1774 1785 1764 
					1757 1793 1791 1767 1765 1744 1743 1739 1742 1746 1745 1757 1768 1775 1786 1765 
					1756 1792 1790 1766 1764 1743 1743 1738 1741 1745 1744 1757 1767 1774 1785 1764 
					1754 1791 1789 1765 1764 1743 1742 1738 1740 1745 1743 1756 1766 1773 1783 1762 
					1753 1789 1787 1764 1762 1742 1740 1736 1739 1743 1742 1754 1765 1771 1782 1760 
					1750 1787 1785 1761 1760 1740 1738 1734 1737 1741 1740 1752 1763 1769 1780 1758 
					1747 1784 1782 1759 1757 1737 1736 1732 1735 1739 1737 1750 1760 1766 1776 1754 
					1744 1780 1779 1756 1754 1734 1733 1729 1731 1736 1734 1747 1757 1763 1773 1751 
					1740 1777 1775 1752 1751 1731 1730 1726 1729 1733 1731 1743 1753 1759 1769 1747 
					1736 1773 1771 1748 1747 1727 1726 1722 1724 1729 1727 1740 1749 1755 1764 1743 
					1731 1767 1766 1743 1743 1722 1722 1717 1720 1724 1722 1735 1744 1750 1759 1738 
					1727 1764 1763 1740 1740 1719 1719 1715 1717 1722 1719 1732 1741 1747 1756 1734 
					1722 1759 1759 1736 1735 1715 1715 1711 1713 1717 1715 1727 1737 1743 1751 1729 
					1717 1754 1754 1731 1731 1711 1710 1707 1710 1714 1712 1724 1733 1738 1747 1724 
					1713 1750 1750 1728 1727 1708 1707 1703 1706 1710 1708 1719 1729 1734 1742 1719 
					1708 1745 1746 1724 1724 1704 1703 1700 1702 1706 1704 1716 1724 1729 1738 1715 
					1703 1741 1741 1719 1719 1700 1700 1696 1698 1703 1701 1712 1720 1725 1733 1710 
					1698 1736 1737 1716 1716 1696 1696 1694 1696 1699 1697 1708 1716 1721 1728 1705 
					1736 1775 1777 1755 1755 1736 1736 1733 1735 1739 1736 1747 1756 1760 1767 1743
					1772 1807 1807 1785 1785 1765 1764 1757 1760 1766 1764 1775 1783 1789 1795 1773>;
			};

			huawei,tianma{
				huawei,name = "huawei,tianma";
				huawei,report_rate_test = <1>; /* 0:disable test, 1:enable test */
				// if is config item is set to 1, the mmi test will always return pass
				huawei,mmi_test_always_pass = <0>;

				huawei,highres_upperlimit = <9999 9999 9999>;
				huawei,highres_lowerlimit = <0xD8F1 0xD8F1 0xD8F1>;/* 0xD8F1 == -9999 */

				huawei,rx_cap_upperlimit = <420>;
				huawei,rx_cap_lowerlimit = <0xFE5C>;

				huawei,tx_cap_upperlimit = <420>;
				huawei,tx_cap_lowerlimit = <0xFE5C>;

				huawei,deltarawimage_upperlimit = <40>;
				huawei,deltarawimage_lowerlimit = <0xFFD8>;

				huawei,f51_ctrl_01_low_sensitivity_val = <0x1b>;
				huawei,f51_ctrl_04_low_sensitivity_val = <0x17>;
				huawei,f01_ctrl_05_low_sensitivity_val = <0x05>;
				huawei,f01_ctrl_09_low_sensitivity_val = <0x04>;

				huawei,fullraw_upperlimit =
					<3890 3788 3761 3684 3651 3654 3654 3662 3662 3662 3661 3674 3736 3796 3805 3896 
					3785 3684 3654 3577 3545 3549 3550 3561 3561 3561 3558 3570 3632 3692 3701 3793 
					3790 3688 3658 3581 3549 3553 3554 3565 3565 3565 3562 3574 3636 3696 3704 3797 
					3747 3643 3615 3538 3505 3510 3510 3520 3520 3520 3518 3530 3592 3650 3659 3753 
					3748 3645 3616 3539 3507 3511 3512 3522 3522 3522 3519 3531 3593 3651 3661 3754 
					3747 3645 3615 3539 3507 3510 3511 3520 3520 3520 3518 3531 3593 3650 3659 3753 
					3744 3640 3612 3535 3503 3507 3508 3518 3519 3519 3515 3528 3589 3647 3657 3750 
					3739 3635 3607 3531 3499 3503 3504 3514 3514 3514 3511 3523 3585 3643 3651 3744 
					3732 3628 3601 3524 3493 3497 3497 3508 3508 3508 3504 3518 3578 3636 3645 3739 
					3726 3620 3593 3516 3485 3489 3491 3500 3501 3500 3496 3510 3570 3628 3636 3731 
					3716 3611 3584 3507 3476 3480 3481 3491 3492 3491 3487 3499 3561 3618 3626 3720 
					3704 3599 3572 3495 3464 3468 3470 3480 3480 3478 3476 3488 3549 3607 3613 3709 
					3690 3585 3558 3483 3451 3456 3457 3468 3468 3466 3462 3474 3537 3593 3600 3696 
					3676 3570 3543 3468 3437 3441 3442 3453 3453 3453 3447 3461 3522 3578 3585 3681 
					3659 3554 3527 3451 3420 3426 3427 3437 3438 3437 3433 3445 3505 3562 3569 3665 
					3642 3537 3510 3434 3403 3408 3410 3420 3420 3419 3415 3427 3488 3545 3550 3646 
					3622 3515 3489 3414 3383 3388 3389 3400 3400 3399 3395 3407 3468 3524 3530 3626 
					3599 3492 3466 3391 3361 3366 3368 3377 3379 3377 3372 3384 3445 3501 3507 3603 
					3576 3470 3445 3369 3338 3345 3346 3356 3357 3356 3352 3362 3423 3478 3483 3580 
					3553 3447 3422 3346 3316 3322 3323 3334 3335 3334 3330 3341 3402 3457 3460 3557 
					3530 3423 3399 3323 3294 3300 3302 3312 3314 3312 3307 3319 3379 3434 3437 3534 
					3505 3399 3375 3299 3271 3276 3279 3289 3291 3289 3284 3295 3354 3410 3412 3508 
					3480 3373 3349 3275 3245 3252 3254 3265 3268 3265 3260 3271 3330 3384 3387 3484 
					3454 3348 3325 3250 3221 3227 3230 3241 3244 3241 3235 3246 3306 3360 3362 3458 
					3429 3322 3299 3225 3196 3203 3206 3217 3219 3217 3211 3222 3280 3334 3335 3431 
					3403 3296 3275 3199 3172 3179 3181 3192 3195 3192 3187 3196 3256 3308 3310 3406 
					3427 3323 3302 3227 3199 3206 3208 3221 3223 3221 3215 3225 3283 3335 3335 3430 
					3408 3303 3281 3208 3180 3188 3191 3203 3206 3203 3196 3207 3265 3316 3316 3411 
					3623 3483 3464 3388 3357 3364 3369 3388 3392 3383 3377 3389 3449 3501 3496 3626>;

				huawei,fullraw_lowerlimit =
					<1873 1823 1810 1773 1758 1759 1759 1763 1763 1763 1762 1769 1799 1827 1832 1875 
					1822 1773 1759 1722 1706 1708 1709 1714 1714 1714 1713 1719 1749 1777 1782 1826 
					1825 1775 1761 1724 1708 1710 1711 1716 1716 1716 1715 1721 1751 1779 1783 1828 
					1804 1754 1740 1703 1688 1690 1690 1695 1695 1695 1693 1699 1729 1757 1762 1807 
					1805 1755 1741 1704 1688 1690 1691 1695 1695 1695 1694 1700 1730 1758 1762 1807 
					1804 1755 1740 1704 1688 1690 1690 1695 1695 1695 1693 1700 1730 1757 1762 1807 
					1803 1753 1739 1702 1686 1688 1689 1693 1694 1694 1692 1699 1728 1756 1760 1805 
					1800 1750 1736 1700 1684 1686 1687 1691 1691 1691 1690 1696 1726 1754 1758 1803 
					1797 1747 1734 1697 1682 1684 1684 1689 1689 1689 1687 1693 1723 1751 1755 1800 
					1794 1743 1730 1693 1678 1680 1680 1685 1686 1685 1683 1690 1719 1747 1751 1796 
					1789 1738 1725 1688 1673 1675 1676 1680 1681 1680 1678 1684 1714 1742 1745 1791 
					1783 1732 1719 1682 1667 1669 1671 1675 1675 1675 1673 1679 1708 1736 1740 1786 
					1777 1726 1713 1677 1662 1664 1664 1669 1669 1669 1667 1673 1703 1730 1733 1779 
					1769 1719 1706 1669 1654 1656 1657 1662 1662 1662 1660 1666 1695 1723 1726 1772 
					1762 1711 1698 1662 1647 1649 1650 1654 1655 1654 1652 1658 1688 1715 1718 1764 
					1753 1703 1690 1653 1638 1641 1641 1647 1647 1646 1644 1650 1679 1706 1709 1755 
					1743 1692 1680 1643 1628 1631 1632 1637 1637 1636 1634 1640 1669 1697 1699 1745 
					1732 1681 1669 1632 1618 1621 1621 1626 1626 1626 1623 1629 1658 1686 1688 1734 
					1721 1671 1658 1622 1607 1610 1611 1615 1616 1615 1613 1619 1648 1675 1677 1723 
					1710 1660 1647 1611 1597 1599 1600 1605 1606 1605 1603 1608 1638 1664 1665 1712 
					1699 1648 1636 1600 1586 1589 1589 1595 1595 1595 1592 1598 1626 1653 1654 1701 
					1688 1636 1625 1588 1574 1577 1578 1584 1584 1584 1581 1586 1615 1641 1643 1689 
					1675 1624 1612 1576 1562 1565 1567 1572 1573 1572 1569 1574 1603 1629 1630 1677 
					1663 1612 1600 1565 1550 1554 1555 1560 1561 1560 1558 1563 1591 1617 1619 1665 
					1651 1599 1588 1552 1539 1542 1543 1548 1550 1548 1546 1551 1579 1605 1606 1652 
					1638 1587 1576 1540 1527 1530 1532 1537 1538 1537 1534 1539 1567 1593 1593 1639 
					1650 1600 1589 1554 1540 1543 1545 1550 1552 1550 1548 1552 1580 1606 1606 1651 
					1641 1590 1580 1545 1531 1535 1536 1542 1543 1542 1539 1544 1572 1597 1597 1642 
					1744 1677 1667 1631 1616 1619 1622 1631 1633 1628 1626 1632 1660 1686 1683 1745>;
			};

			huawei,ctc {
				huawei,name = "huawei,ctc";
				huawei,report_rate_test = <1>; /* 0:disable test, 1:enable test */
				// if is config item is set to 1, the mmi test will always return pass
				huawei,mmi_test_always_pass = <0>;

				huawei,highres_upperlimit = <9999 9999 9999>;
				huawei,highres_lowerlimit = <0xD8F1 0xD8F1 0xD8F1>;/* 0xD8F1 == -9999 */

				huawei,rx_cap_upperlimit = <9999>;
				huawei,rx_cap_lowerlimit = <0xD8F1>;

				huawei,tx_cap_upperlimit = <9999>;
				huawei,tx_cap_lowerlimit = <0xD8F1>;

				huawei,deltarawimage_upperlimit = <9999>;
				huawei,deltarawimage_lowerlimit = <0xD8F1>;

				huawei,f51_ctrl_01_low_sensitivity_val = <0x1b>;
				huawei,f51_ctrl_04_low_sensitivity_val = <0x17>;
				huawei,f01_ctrl_05_low_sensitivity_val = <0x05>;
				huawei,f01_ctrl_09_low_sensitivity_val = <0x04>;

				huawei,fullraw_upperlimit =
					<9999 9999 9999 9999 9999 9999 9999 9999 9999 9999 9999 9999 9999 9999 9999 9999 9999 9999 9999 9999 9999 9999 9999 9999 9999 9999 9999 9999
					9999 9999 9999 9999 9999 9999 9999 9999 9999 9999 9999 9999 9999 9999 9999 9999 9999 9999 9999 9999 9999 9999 9999 9999 9999 9999 9999 9999
					9999 9999 9999 9999 9999 9999 9999 9999 9999 9999 9999 9999 9999 9999 9999 9999 9999 9999 9999 9999 9999 9999 9999 9999 9999 9999 9999 9999
					9999 9999 9999 9999 9999 9999 9999 9999 9999 9999 9999 9999 9999 9999 9999 9999 9999 9999 9999 9999 9999 9999 9999 9999 9999 9999 9999 9999
					9999 9999 9999 9999 9999 9999 9999 9999 9999 9999 9999 9999 9999 9999 9999 9999 9999 9999 9999 9999 9999 9999 9999 9999 9999 9999 9999 9999
					9999 9999 9999 9999 9999 9999 9999 9999 9999 9999 9999 9999 9999 9999 9999 9999 9999 9999 9999 9999 9999 9999 9999 9999 9999 9999 9999 9999
					9999 9999 9999 9999 9999 9999 9999 9999 9999 9999 9999 9999 9999 9999 9999 9999 9999 9999 9999 9999 9999 9999 9999 9999 9999 9999 9999 9999
					9999 9999 9999 9999 9999 9999 9999 9999 9999 9999 9999 9999 9999 9999 9999 9999 9999 9999 9999 9999 9999 9999 9999 9999 9999 9999 9999 9999
					9999 9999 9999 9999 9999 9999 9999 9999 9999 9999 9999 9999 9999 9999 9999 9999 9999 9999 9999 9999 9999 9999 9999 9999 9999 9999 9999 9999
					9999 9999 9999 9999 9999 9999 9999 9999 9999 9999 9999 9999 9999 9999 9999 9999 9999 9999 9999 9999 9999 9999 9999 9999 9999 9999 9999 9999
					9999 9999 9999 9999 9999 9999 9999 9999 9999 9999 9999 9999 9999 9999 9999 9999 9999 9999 9999 9999 9999 9999 9999 9999 9999 9999 9999 9999
					9999 9999 9999 9999 9999 9999 9999 9999 9999 9999 9999 9999 9999 9999 9999 9999 9999 9999 9999 9999 9999 9999 9999 9999 9999 9999 9999 9999
					9999 9999 9999 9999 9999 9999 9999 9999 9999 9999 9999 9999 9999 9999 9999 9999 9999 9999 9999 9999 9999 9999 9999 9999 9999 9999 9999 9999
					9999 9999 9999 9999 9999 9999 9999 9999 9999 9999 9999 9999 9999 9999 9999 9999 9999 9999 9999 9999 9999 9999 9999 9999 9999 9999 9999 9999
					9999 9999 9999 9999 9999 9999 9999 9999 9999 9999 9999 9999 9999 9999 9999 9999 9999 9999 9999 9999 9999 9999 9999 9999 9999 9999 9999 9999
					9999 9999 9999 9999 9999 9999 9999 9999 9999 9999 9999 9999 9999 9999 9999 9999 9999 9999 9999 9999 9999 9999 9999 9999 9999 9999 9999 9999>;

				huawei,fullraw_lowerlimit =
					<0 0 0 0 0 0 0 0 0 0 0 0 0 0 0 0 0 0 0 0 0 0 0 0 0 0 0 0
					0 0 0 0 0 0 0 0 0 0 0 0 0 0 0 0 0 0 0 0 0 0 0 0 0 0 0 0
					0 0 0 0 0 0 0 0 0 0 0 0 0 0 0 0 0 0 0 0 0 0 0 0 0 0 0 0
					0 0 0 0 0 0 0 0 0 0 0 0 0 0 0 0 0 0 0 0 0 0 0 0 0 0 0 0
					0 0 0 0 0 0 0 0 0 0 0 0 0 0 0 0 0 0 0 0 0 0 0 0 0 0 0 0
					0 0 0 0 0 0 0 0 0 0 0 0 0 0 0 0 0 0 0 0 0 0 0 0 0 0 0 0
					0 0 0 0 0 0 0 0 0 0 0 0 0 0 0 0 0 0 0 0 0 0 0 0 0 0 0 0
					0 0 0 0 0 0 0 0 0 0 0 0 0 0 0 0 0 0 0 0 0 0 0 0 0 0 0 0
					0 0 0 0 0 0 0 0 0 0 0 0 0 0 0 0 0 0 0 0 0 0 0 0 0 0 0 0
					0 0 0 0 0 0 0 0 0 0 0 0 0 0 0 0 0 0 0 0 0 0 0 0 0 0 0 0
					0 0 0 0 0 0 0 0 0 0 0 0 0 0 0 0 0 0 0 0 0 0 0 0 0 0 0 0
					0 0 0 0 0 0 0 0 0 0 0 0 0 0 0 0 0 0 0 0 0 0 0 0 0 0 0 0
					0 0 0 0 0 0 0 0 0 0 0 0 0 0 0 0 0 0 0 0 0 0 0 0 0 0 0 0
					0 0 0 0 0 0 0 0 0 0 0 0 0 0 0 0 0 0 0 0 0 0 0 0 0 0 0 0
					0 0 0 0 0 0 0 0 0 0 0 0 0 0 0 0 0 0 0 0 0 0 0 0 0 0 0 0
					0 0 0 0 0 0 0 0 0 0 0 0 0 0 0 0 0 0 0 0 0 0 0 0 0 0 0 0>;
			};

			huawei,cmi {
				huawei,name = "huawei,cmi";
				huawei,report_rate_test = <1>; /* 0:disable test, 1:enable test */
				// if is config item is set to 1, the mmi test will always return pass
				huawei,mmi_test_always_pass = <0>;

				huawei,highres_upperlimit = <9999 9999 9999>;
				huawei,highres_lowerlimit = <0xD8F1 0xD8F1 0xD8F1>;/* 0xD8F1 == -9999 */

				huawei,rx_cap_upperlimit = <9999>;
				huawei,rx_cap_lowerlimit = <0xD8F1>;

				huawei,tx_cap_upperlimit = <9999>;
				huawei,tx_cap_lowerlimit = <0xD8F1>;

				huawei,deltarawimage_upperlimit = <9999>;
				huawei,deltarawimage_lowerlimit = <0xD8F1>;

				huawei,f51_ctrl_01_low_sensitivity_val = <0x1b>;
				huawei,f51_ctrl_04_low_sensitivity_val = <0x17>;
				huawei,f01_ctrl_05_low_sensitivity_val = <0x05>;
				huawei,f01_ctrl_09_low_sensitivity_val = <0x04>;

				huawei,fullraw_upperlimit =
					<9999 9999 9999 9999 9999 9999 9999 9999 9999 9999 9999 9999 9999 9999 9999 9999 9999 9999 9999 9999 9999 9999 9999 9999 9999 9999 9999 9999
					9999 9999 9999 9999 9999 9999 9999 9999 9999 9999 9999 9999 9999 9999 9999 9999 9999 9999 9999 9999 9999 9999 9999 9999 9999 9999 9999 9999
					9999 9999 9999 9999 9999 9999 9999 9999 9999 9999 9999 9999 9999 9999 9999 9999 9999 9999 9999 9999 9999 9999 9999 9999 9999 9999 9999 9999
					9999 9999 9999 9999 9999 9999 9999 9999 9999 9999 9999 9999 9999 9999 9999 9999 9999 9999 9999 9999 9999 9999 9999 9999 9999 9999 9999 9999
					9999 9999 9999 9999 9999 9999 9999 9999 9999 9999 9999 9999 9999 9999 9999 9999 9999 9999 9999 9999 9999 9999 9999 9999 9999 9999 9999 9999
					9999 9999 9999 9999 9999 9999 9999 9999 9999 9999 9999 9999 9999 9999 9999 9999 9999 9999 9999 9999 9999 9999 9999 9999 9999 9999 9999 9999
					9999 9999 9999 9999 9999 9999 9999 9999 9999 9999 9999 9999 9999 9999 9999 9999 9999 9999 9999 9999 9999 9999 9999 9999 9999 9999 9999 9999
					9999 9999 9999 9999 9999 9999 9999 9999 9999 9999 9999 9999 9999 9999 9999 9999 9999 9999 9999 9999 9999 9999 9999 9999 9999 9999 9999 9999
					9999 9999 9999 9999 9999 9999 9999 9999 9999 9999 9999 9999 9999 9999 9999 9999 9999 9999 9999 9999 9999 9999 9999 9999 9999 9999 9999 9999
					9999 9999 9999 9999 9999 9999 9999 9999 9999 9999 9999 9999 9999 9999 9999 9999 9999 9999 9999 9999 9999 9999 9999 9999 9999 9999 9999 9999
					9999 9999 9999 9999 9999 9999 9999 9999 9999 9999 9999 9999 9999 9999 9999 9999 9999 9999 9999 9999 9999 9999 9999 9999 9999 9999 9999 9999
					9999 9999 9999 9999 9999 9999 9999 9999 9999 9999 9999 9999 9999 9999 9999 9999 9999 9999 9999 9999 9999 9999 9999 9999 9999 9999 9999 9999
					9999 9999 9999 9999 9999 9999 9999 9999 9999 9999 9999 9999 9999 9999 9999 9999 9999 9999 9999 9999 9999 9999 9999 9999 9999 9999 9999 9999
					9999 9999 9999 9999 9999 9999 9999 9999 9999 9999 9999 9999 9999 9999 9999 9999 9999 9999 9999 9999 9999 9999 9999 9999 9999 9999 9999 9999
					9999 9999 9999 9999 9999 9999 9999 9999 9999 9999 9999 9999 9999 9999 9999 9999 9999 9999 9999 9999 9999 9999 9999 9999 9999 9999 9999 9999
					9999 9999 9999 9999 9999 9999 9999 9999 9999 9999 9999 9999 9999 9999 9999 9999 9999 9999 9999 9999 9999 9999 9999 9999 9999 9999 9999 9999>;

				huawei,fullraw_lowerlimit =
					<0 0 0 0 0 0 0 0 0 0 0 0 0 0 0 0 0 0 0 0 0 0 0 0 0 0 0 0
					0 0 0 0 0 0 0 0 0 0 0 0 0 0 0 0 0 0 0 0 0 0 0 0 0 0 0 0
					0 0 0 0 0 0 0 0 0 0 0 0 0 0 0 0 0 0 0 0 0 0 0 0 0 0 0 0
					0 0 0 0 0 0 0 0 0 0 0 0 0 0 0 0 0 0 0 0 0 0 0 0 0 0 0 0
					0 0 0 0 0 0 0 0 0 0 0 0 0 0 0 0 0 0 0 0 0 0 0 0 0 0 0 0
					0 0 0 0 0 0 0 0 0 0 0 0 0 0 0 0 0 0 0 0 0 0 0 0 0 0 0 0
					0 0 0 0 0 0 0 0 0 0 0 0 0 0 0 0 0 0 0 0 0 0 0 0 0 0 0 0
					0 0 0 0 0 0 0 0 0 0 0 0 0 0 0 0 0 0 0 0 0 0 0 0 0 0 0 0
					0 0 0 0 0 0 0 0 0 0 0 0 0 0 0 0 0 0 0 0 0 0 0 0 0 0 0 0
					0 0 0 0 0 0 0 0 0 0 0 0 0 0 0 0 0 0 0 0 0 0 0 0 0 0 0 0
					0 0 0 0 0 0 0 0 0 0 0 0 0 0 0 0 0 0 0 0 0 0 0 0 0 0 0 0
					0 0 0 0 0 0 0 0 0 0 0 0 0 0 0 0 0 0 0 0 0 0 0 0 0 0 0 0
					0 0 0 0 0 0 0 0 0 0 0 0 0 0 0 0 0 0 0 0 0 0 0 0 0 0 0 0
					0 0 0 0 0 0 0 0 0 0 0 0 0 0 0 0 0 0 0 0 0 0 0 0 0 0 0 0
					0 0 0 0 0 0 0 0 0 0 0 0 0 0 0 0 0 0 0 0 0 0 0 0 0 0 0 0
					0 0 0 0 0 0 0 0 0 0 0 0 0 0 0 0 0 0 0 0 0 0 0 0 0 0 0 0>;
			};
		};
	};

	/*To disable gen-vkeys.c probe,avoid generate kobject*/
	gen-vkeys {
		compatible = "huawei,gen-vkeys";
		label = "synaptics_rmi4_i2c";
		qcom,disp-maxx = <720>;
		qcom,disp-maxy = <1280>;
		qcom,panel-maxx = <720>;
		qcom,panel-maxy = <1369>;
		qcom,key-codes = <158 172 139>;
	};

};
